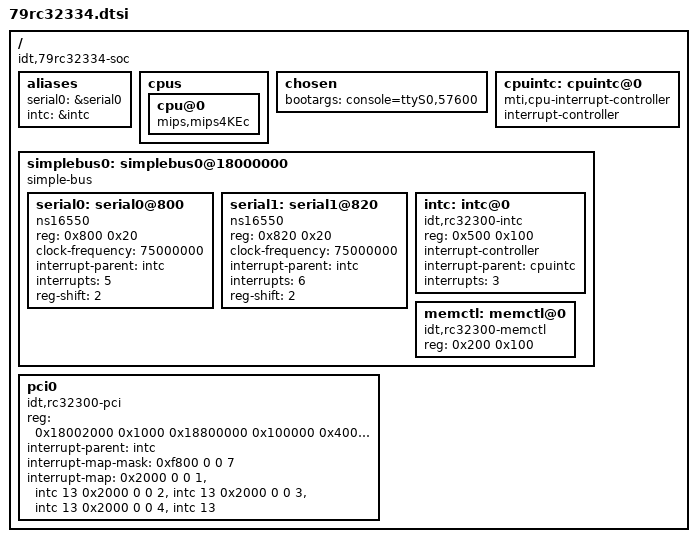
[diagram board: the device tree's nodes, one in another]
/ {
	#address-cells = <1>;
	#size-cells = <1>;
	compatible = "idt,79rc32334-soc";

	aliases {
		serial0 = &serial0;
		intc = &intc;
	};

	cpus {
		cpu@0 {
			compatible = "mips,mips4KEc";
		};
	};

	chosen {
		bootargs = "console=ttyS0,57600";
	};

	cpuintc: cpuintc@0 {
		#address-cells = <0>;
		#interrupt-cells = <1>;
		interrupt-controller;
		compatible = "mti,cpu-interrupt-controller";
	};

	simplebus0: simplebus0@18000000 {
		compatible = "simple-bus";
		ranges = <0x0 0x18000000 0x1FFFFF>;

		#address-cells = <1>;
		#size-cells = <1>;

		serial0: serial0@800 {
			compatible = "ns16550";
			reg = <0x800 0x20>;
			clock-frequency = <75000000>;
			interrupt-parent = <&intc>;
			interrupts = <5>;
			reg-shift = <2>;
		};

		serial1: serial1@820 {
			compatible = "ns16550";
			reg = <0x820 0x20>;
			clock-frequency = <75000000>;
			interrupt-parent = <&intc>;
			interrupts = <6>;
			reg-shift = <2>;
		};

		intc: intc@0 {
			compatible = "idt,rc32300-intc";
			reg = <0x500 0x100>;

			interrupt-controller;
			#interrupt-cells = <1>;

			interrupt-parent = <&cpuintc>;
			interrupts = <3>;
		};

		memctl: memctl@0 {
			compatible = "idt,rc32300-memctl";
			reg = <0x200 0x100>;
		};
/*

		sysc: sysc@0 {
			compatible = "ralink,rt2880-sysc";
			reg = <0x000 0x100>;
		};

		timer: timer@100 {
			compatible = "ralink,rt2880-timer";
			reg = <0x100 0x20>;

			interrupt-parent = <&intc>;
			interrupts = <1>;

			status = "disabled";
		};

		watchdog: watchdog@120 {
			compatible = "ralink,rt2880-wdt";
			reg = <0x120 0x10>;
		};


		memc: memc@300 {
			compatible = "ralink,rt2880-memc";
			reg = <0x300 0x100>;
		};

		gpio0: gpio@600 {
			compatible = "ralink,rt2880-gpio";
			reg = <0x600 0x34>;

			gpio-controller;
			#gpio-cells = <2>;

			ralink,gpio-base = <0>;
			ralink,num-gpios = <24>;
			ralink,register-map = [ 00 04 08 0c
						20 24 28 2c
						30 34 ];

			interrupt-parent = <&intc>;
			interrupts = <7>;
		};
*/

	};

	pci0 {
		compatible = "idt,rc32300-pci";
		reg = <0x18002000 0x1000
			0x18800000 0x100000
			0x40000000 0x10000000
			0x60000000 0x10000000
			0x18c00000 0x400000>;
		interrupt-parent = <&intc>;
		#address-cells = <3>;
		#size-cells = <2>;
		#interrupt-cells = <1>;
		interrupt-map-mask = <0xf800 0 0 7>;
		interrupt-map = <0x2000 0 0 1 &intc 13
				0x2000 0 0 2 &intc 13
				0x2000 0 0 3 &intc 13
				0x2000 0 0 4 &intc 13>;
/*
		interrupt-controller;
		#interrupt-cells = <1>;
		interrupt-parent = <&intc>;
		interrupts = <11 12 13>;
*/

	};

};
